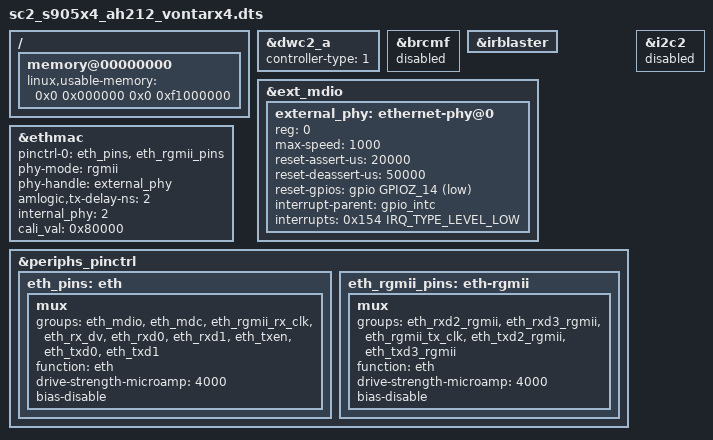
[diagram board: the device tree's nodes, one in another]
// SPDX-License-Identifier: (GPL-2.0+ OR MIT)
/*
 * Copyright (c) 2019 Amlogic, Inc. All rights reserved.
 */

#include "sc2_s905x4_ah212_drm.dts"
#include "remote-vontarx4-34btns.dtsi"

/ {
	memory@00000000 {
		/* SC2 DRAM is [0, 0xf1000000); MMIO starts at 0xf1000000. */
		linux,usable-memory = <0x0 0x000000 0x0 0xf1000000>;
	};
};

&dwc2_a {
	/** 0: normal, 1: otg+dwc3 host only, 2: otg+dwc3 device only*/
	controller-type = <1>;
};

/* Wi-Fi is driven by the out-of-tree DHD driver, not brcmfmac. */
&brcmf {
	status = "disabled";
};

&irblaster {
	status = "okay";
};

/* External RGMII PHY instead of the AH212 internal RMII PHY. */
&ext_mdio {
	external_phy: ethernet-phy@0 {
		reg = <0>;
		max-speed = <1000>;
		reset-assert-us = <20000>;
		reset-deassert-us = <50000>;
		reset-gpios = <&gpio GPIOZ_14 (GPIO_ACTIVE_LOW | GPIO_OPEN_DRAIN)>;
		interrupt-parent = <&gpio_intc>;
		interrupts = <0x154 IRQ_TYPE_LEVEL_LOW>;
	};
};

&ethmac {
	pinctrl-0 = <&eth_pins>, <&eth_rgmii_pins>;
	pinctrl-names = "default";
	phy-mode = "rgmii";
	phy-handle = <&external_phy>;
	amlogic,tx-delay-ns = <2>;
	/* 1: inphy, 2: exphy */
	internal_phy = <2>;
	cali_val = <0x80000>;
	/*
	 * mc_val is the internal PHY RMII setup. The driver writes it to
	 * PRG_ETH0 after RGMII init, which would clear RGMII mode.
	 */
	/delete-property/ mc_val;
	/delete-property/ mac_wol;
	/delete-property/ mdns_wkup;
};

&periphs_pinctrl {
	eth_pins: eth {
		mux {
			groups = "eth_mdio",
				"eth_mdc",
				"eth_rgmii_rx_clk",
				"eth_rx_dv",
				"eth_rxd0",
				"eth_rxd1",
				"eth_txen",
				"eth_txd0",
				"eth_txd1";
			function = "eth";
			drive-strength-microamp = <4000>;
			bias-disable;
		};
	};

	eth_rgmii_pins: eth-rgmii {
		mux {
			groups = "eth_rxd2_rgmii",
				"eth_rxd3_rgmii",
				"eth_rgmii_tx_clk",
				"eth_txd2_rgmii",
				"eth_txd3_rgmii";
			function = "eth";
			drive-strength-microamp = <4000>;
			bias-disable;
		};
	};
};

/* i2c2_pins3 (i2c2_sda_z14 / i2c2_scl_z15) claims GPIOZ_14, the PHY reset. */
&i2c2 {
	status = "disabled";
};
